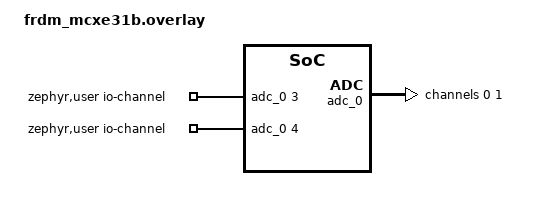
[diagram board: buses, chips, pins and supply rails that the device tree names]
/*
 * SPDX-License-Identifier: Apache-2.0
 *
 * Copyright 2025 NXP
 */

#include <zephyr/dt-bindings/adc/adc.h>

/ {
	zephyr,user {
		io-channels = <&adc_0 3>, <&adc_0 4>;
	};
};

&adc_0 {
	#address-cells = <1>;
	#size-cells = <0>;

	channel@3 {
		reg = <0>;
		zephyr,gain = "ADC_GAIN_1";
		zephyr,reference = "ADC_REF_INTERNAL";
		zephyr,acquisition-time = <ADC_ACQ_TIME_DEFAULT>;
		zephyr,resolution = <12>;
	};

	channel@4 {
		reg = <1>;
		zephyr,gain = "ADC_GAIN_1";
		zephyr,reference = "ADC_REF_INTERNAL";
		zephyr,acquisition-time = <ADC_ACQ_TIME_DEFAULT>;
		zephyr,resolution = <12>;
	};
};
